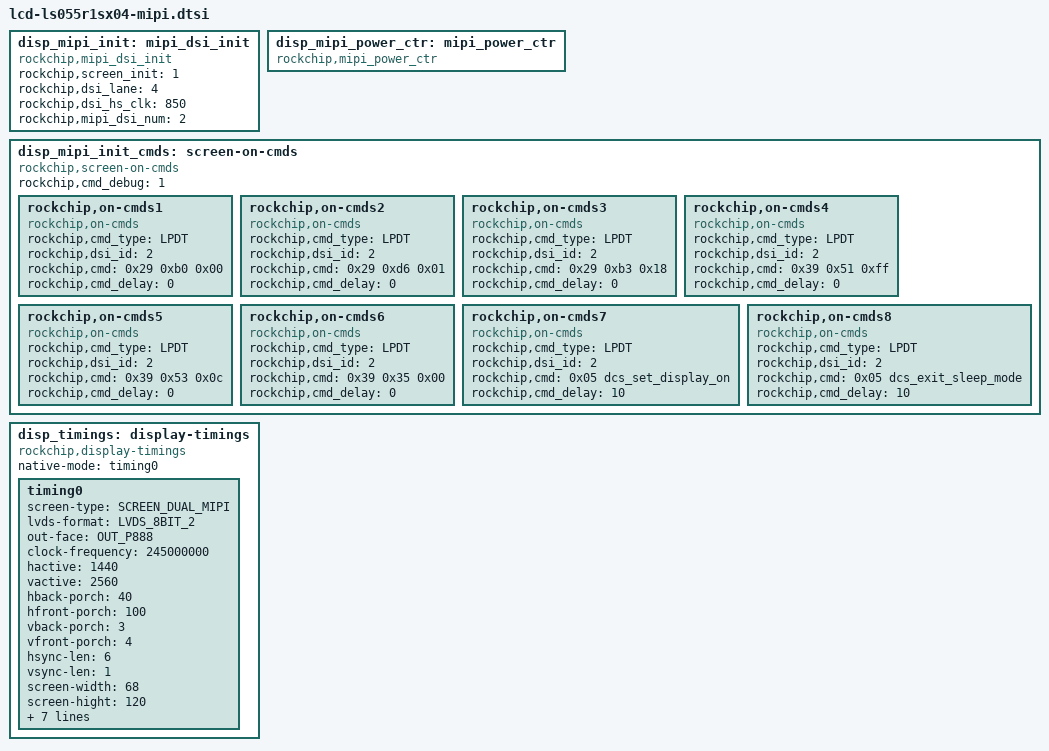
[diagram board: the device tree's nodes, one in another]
/*
 * Copyright (c) 2016 Fuzhou Rockchip Electronics Co., Ltd
 *
 * This file is dual-licensed: you can use it either under the terms
 * of the GPL or the X11 license, at your option. Note that this dual
 * licensing only applies to this file, and not this project as a
 * whole.
 *
 *  a) This file is free software; you can redistribute it and/or
 *     modify it under the terms of the GNU General Public License as
 *     published by the Free Software Foundation; either version 2 of the
 *     License, or (at your option) any later version.
 *
 *     This file is distributed in the hope that it will be useful,
 *     but WITHOUT ANY WARRANTY; without even the implied warranty of
 *     MERCHANTABILITY or FITNESS FOR A PARTICULAR PURPOSE.  See the
 *     GNU General Public License for more details.
 *
 * Or, alternatively,
 *
 *  b) Permission is hereby granted, free of charge, to any person
 *     obtaining a copy of this software and associated documentation
 *     files (the "Software"), to deal in the Software without
 *     restriction, including without limitation the rights to use,
 *     copy, modify, merge, publish, distribute, sublicense, and/or
 *     sell copies of the Software, and to permit persons to whom the
 *     Software is furnished to do so, subject to the following
 *     conditions:
 *
 *     The above copyright notice and this permission notice shall be
 *     included in all copies or substantial portions of the Software.
 *
 *     THE SOFTWARE IS PROVIDED "AS IS", WITHOUT WARRANTY OF ANY KIND,
 *     EXPRESS OR IMPLIED, INCLUDING BUT NOT LIMITED TO THE WARRANTIES
 *     OF MERCHANTABILITY, FITNESS FOR A PARTICULAR PURPOSE AND
 *     NONINFRINGEMENT. IN NO EVENT SHALL THE AUTHORS OR COPYRIGHT
 *     HOLDERS BE LIABLE FOR ANY CLAIM, DAMAGES OR OTHER LIABILITY,
 *     WHETHER IN AN ACTION OF CONTRACT, TORT OR OTHERWISE, ARISING
 *     FROM, OUT OF OR IN CONNECTION WITH THE SOFTWARE OR THE USE OR
 *     OTHER DEALINGS IN THE SOFTWARE.
 *
 * include/dt-bindings/display/screen-timing/lcd-ls055r1sx04-mipi.dtsi
 * author: xbl@rock-chips.com
 * create date: 2016-05-16
 * lcd model: sharp ls055r1sx04
 * resolution: 1440 * 2560
 * mipi channel: double
 */

/* about mipi */
disp_mipi_init: mipi_dsi_init{
	compatible = "rockchip,mipi_dsi_init";
	rockchip,screen_init	= <1>;
	rockchip,dsi_lane	= <4>;
	rockchip,dsi_hs_clk	= <850>;
	rockchip,mipi_dsi_num	= <2>;
};

disp_mipi_power_ctr: mipi_power_ctr {
	compatible = "rockchip,mipi_power_ctr";
	/* mipi_lcd_rst:mipi_lcd_rst{
			compatible = "rockchip,lcd_rst";
			rockchip,gpios = <&gpio2 GPIO_B7 GPIO_ACTIVE_LOW>;
			rockchip,delay = <100>;
	};
	mipi_lcd_en:mipi_lcd_en {
			compatible = "rockchip,lcd_en";
			rockchip,gpios = <&gpio0 GPIO_C1 GPIO_ACTIVE_HIGH>;
			rockchip,delay = <100>;
	};
	*/
};

disp_mipi_init_cmds: screen-on-cmds {
	compatible = "rockchip,screen-on-cmds";
	rockchip,cmd_debug = <1>;
	rockchip,on-cmds1 {
			compatible = "rockchip,on-cmds";
			rockchip,cmd_type = <LPDT>;
			rockchip,dsi_id = <2>;
			rockchip,cmd = <0x29 0xb0 0x00>;
			rockchip,cmd_delay = <0>;
	};
	rockchip,on-cmds2 {
			compatible = "rockchip,on-cmds";
			rockchip,cmd_type = <LPDT>;
			rockchip,dsi_id = <2>;
			rockchip,cmd = <0x29 0xd6 0x01>;
			rockchip,cmd_delay = <0>;
	};
	rockchip,on-cmds3 {
			compatible = "rockchip,on-cmds";
			rockchip,cmd_type = <LPDT>;
			rockchip,dsi_id = <2>;
			rockchip,cmd = <0x29 0xb3 0x18>;
			rockchip,cmd_delay = <0>;
	};
	rockchip,on-cmds4 {
			compatible = "rockchip,on-cmds";
			rockchip,cmd_type = <LPDT>;
			rockchip,dsi_id = <2>;
			rockchip,cmd = <0x39 0x51 0xff>;
			rockchip,cmd_delay = <0>;
	};
	rockchip,on-cmds5 {
			compatible = "rockchip,on-cmds";
			rockchip,cmd_type = <LPDT>;
			rockchip,dsi_id = <2>;
			rockchip,cmd = <0x39 0x53 0x0c>;
			rockchip,cmd_delay = <0>;
	};
	rockchip,on-cmds6 {
			compatible = "rockchip,on-cmds";
			rockchip,cmd_type = <LPDT>;
			rockchip,dsi_id = <2>;
			rockchip,cmd = <0x39 0x35 0x00>;
			rockchip,cmd_delay = <0>;
	};
/*
	rockchip,on-cmds7 {
			compatible = "rockchip,on-cmds";
			rockchip,cmd_type = <LPDT>;
			rockchip,dsi_id = <2>;
			rockchip,cmd = <0x29 0xb0 0x03>;
			rockchip,cmd_delay = <0>;
	};
*/
	rockchip,on-cmds7 {
			compatible = "rockchip,on-cmds";
			rockchip,cmd_type = <LPDT>;
			rockchip,dsi_id = <2>;
			rockchip,cmd = <0x05 dcs_set_display_on>;
			rockchip,cmd_delay = <10>;
	};
	rockchip,on-cmds8 {
			compatible = "rockchip,on-cmds";
			rockchip,cmd_type = <LPDT>;
			rockchip,dsi_id = <2>;
			rockchip,cmd = <0x05 dcs_exit_sleep_mode>;
			rockchip,cmd_delay = <10>;
	};
};

disp_timings: display-timings {
	native-mode = <&timing0>;
	compatible = "rockchip,display-timings";
	timing0: timing0 {
		screen-type = <SCREEN_DUAL_MIPI>;
		lvds-format = <LVDS_8BIT_2>;
		out-face    = <OUT_P888>;
		clock-frequency = <245000000>;
		hactive = <1440>;
		vactive = <2560>;
		hback-porch = <40>;
		hfront-porch = <100>;
		vback-porch = <3>;
		vfront-porch = <4>;
		hsync-len = <6>;
		vsync-len = <1>;
		screen-width = <68>;
		screen-hight = <120>;
		hsync-active = <0>;
		vsync-active = <0>;
		de-active = <0>;
		pixelclk-active = <0>;
		swap-rb = <0>;
		swap-rg = <0>;
		swap-gb = <0>;
	};
};
